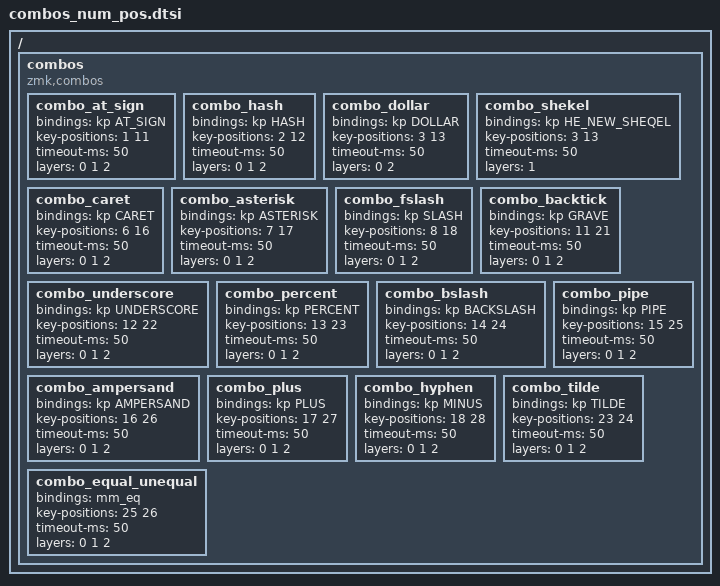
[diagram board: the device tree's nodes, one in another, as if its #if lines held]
/*
* KEY POSITIONS
* 34 Key Matrix
* ╭─────────────────────╮ ╭─────────────────────╮
* │ LT4 LT3 LT2 LT1 LT0 │ │ RT0 RT1 RT2 RT3 RT4 │
* │ LM4 LM3 LM2 LM1 LM0 │ │ RM0 RM1 RM2 RM3 RM4 │
* │ LB4 LB3 LB2 LB1 LB0 │ │ RB0 RB1 RB2 RB3 RB4 │
* ╰───────────╮ LH1 LH0 │ │ RH0 RH1 ╭───────────╯
*             ╰─────────╯ ╰─────────╯ 
*
* ╭────────────────╮ ╭────────────────╮
* │  0  1  2  3  4 │ │  5  6  7  8  9 │
* │ 10 11 12 13 14 │ │ 15 16 17 18 19 │
* │ 20 21 22 23 24 │ │ 25 26 27 28 29 │
* ╰─────────╮ 30 31│ │ 32 33╭─────────╯
*           ╰──────╯ ╰──────╯   
*
* 32 Key Matrix
* ╭────────────────╮ ╭────────────────╮
* │  0  1  2  3  4 │ │  5  6  7  8  9 │
* │ 10 11 12 13 14 │ │ 15 16 17 18 19 │
* ╰──╮ 20 21 22 23 │ │ 24 25 26 27 ╭──╯
*    ╰─────╮ 28 29 │ │ 30 31 ╭─────╯
*          ╰───────╯ ╰───────╯     
* 30 Key Matrix      
* ╭────────────────╮ ╭────────────────╮
* │  0  1  2  3  4 │ │  5  6  7  8  9 │
* │ 10 11 12 13 14 │ │ 15 16 17 18 19 │
* ╰──╮ 20 21 22    │ │    23 24 25 ╭──╯
*    ╰─────╮ 26 27 │ │ 28 29 ╭─────╯
*          ╰───────╯ ╰───────╯    
*/

/*
* Source: https://github.com/caksoylar/zmk-config
*/

#define COMBO(NAME, BINDINGS, KEYPOS, LAYERS, TERM, QUICKTAP, ...) \
    combo_##NAME { \
        timeout-ms = <TERM>; \
        bindings = <BINDINGS>; \
        key-positions = <KEYPOS>; \
        layers = <LAYERS>; \
        require-prior-idle-ms = <QUICKTAP>; \
		__VA_ARGS__ \
    };

/ {
    combos {
        compatible = "zmk,combos";

// Layers
#ifdef 34_KEY
COMBO(english,        &to ENG,        30 33, ENG SYS FUN BLTH,     50, 50)
COMBO(heb_to_eng,     &to ENG,        30 33, HEB,                  50, 50)
#endif
#ifdef 32_KEY
COMBO(english,        &to ENG,        28 31, ENG SYS FUN BLTH,     50, 50)
COMBO(heb_to_eng,     &to ENG,        28 31, HEB,                  50, 50)
#endif
#ifdef 30_KEY
COMBO(english,        &to ENG,        26 29, ENG SYS FUN BLTH,     50, 50)
COMBO(heb_to_eng,     &to ENG,        26 29, HEB,                  50, 50)
#endif

COMBO(hebrew,         &to_heb,        14 15, ENG SYS FUN BLTH,     50, 50)
COMBO(blth_l,         &to BLTH,       1 2 3, ENG HEB SYS FUN BLTH, 50, 50)
COMBO(blth_r,         &to BLTH,       6 7 8, ENG HEB SYS FUN BLTH, 50, 50)
        
// General
COMBO(capsword,       &caps_word,     4 5,   ENG HEB,              50, 50)
COMBO(alt_tab,        &mm_altb,       0 10,  ENG HEB SYS FUN,      50, 50)
COMBO(escape,         &kp ESCAPE,     4 14,  ENG HEB SYS FUN,      50, 50)
COMBO(bspc_del,       &mm_back_del,   5 15,  ENG HEB SYS FUN,      50, 50)
COMBO(return,         &kp RETURN,     9 19,  ENG HEB SYS FUN,      50, 50)

// Shortcuts
COMBO(copy,           &kp LC(C),      0 1,   ENG HEB SYS FUN,      50, 50)
COMBO(paste,          &mm_paste,      8 9,   ENG HEB SYS FUN,      50, 50)
COMBO(undo,           &kp LC(Z),      0 11,  ENG HEB SYS FUN,      50, 50)
COMBO(redo,           &kp LC(Y),      9 18,  ENG HEB SYS FUN,      50, 50)

// Top Row

// Left
COMBO(lte,            &mm_le,         1 2,   ENG SYS,              50, 50)
COMBO(h_lte,          &mm_hle,        1 2,   ENG SYS,              50, 50)
COMBO(brkt_brce_l,    &kp LBKT,       2 3,   ENG SYS,              50, 50)
COMBO(h_brkt_brce_l,  &kp HE_LBKT,    2 3,   ENG SYS,              50, 50)
COMBO(par_l,          &kp LPAR,       3 4,   ENG SYS,              50, 50)
COMBO(h_par_l,        &kp HE_LPAR,    3 4,   ENG SYS,              50, 50)
// Right
COMBO(par_r,          &kp RPAR,       3 4,   ENG SYS,              50, 50)
COMBO(h_par_r,        &kp HE_RPAR,    3 4,   ENG SYS,              50, 50)
COMBO(brkt_brce_r,    &kp RBKT,       2 3,   ENG SYS,              50, 50)
COMBO(h_brkt_brce_r,  &kp HE_RBKT,    2 3,   ENG SYS,              50, 50)
COMBO(gte,            &mm_ge,         1 2,   ENG SYS,              50, 50)
COMBO(h_gte,          &mm_hge,        1 2,   ENG SYS,              50, 50)

        // Top-Home 
        // Left

        combo_at_sign {
            bindings = <&kp AT_SIGN>;
            key-positions = <1 11>;
            timeout-ms = <50>;
            layers = <0 1 2>;
        };

        combo_hash {
            bindings = <&kp HASH>;
            key-positions = <2 12>;
            timeout-ms = <50>;
            layers = <0 1 2>;
        };

        combo_dollar {
            bindings = <&kp DOLLAR>;
            key-positions = <3 13>;
            timeout-ms = <50>;
            layers = <0 2>;
        };

        combo_shekel {
            bindings = <&kp HE_NEW_SHEQEL>;
            key-positions = <3 13>;
            timeout-ms = <50>;
            layers = <1>;
        };

        // Right

        combo_caret {
            bindings = <&kp CARET>;
            key-positions = <6 16>;
            timeout-ms = <50>;
            layers = <0 1 2>;
        };

        combo_asterisk {
            bindings = <&kp ASTERISK>;
            key-positions = <7 17>;
            timeout-ms = <50>;
            layers = <0 1 2>;
        };

        combo_fslash {
            bindings = <&kp SLASH>;
            key-positions = <8 18>;
            timeout-ms = <50>;
            layers = <0 1 2>;
        };

        // Home-Bottom

        combo_backtick {
            bindings = <&kp GRAVE>;
            key-positions = <11 21>;
            timeout-ms = <50>;
            layers = <0 1 2>;
        };

        combo_underscore {
            bindings = <&kp UNDERSCORE>;
            key-positions = <12 22>;
            timeout-ms = <50>;
            layers = <0 1 2>;
        };

        combo_percent {
            bindings = <&kp PERCENT>;
            key-positions = <13 23>;
            timeout-ms = <50>;
            layers = <0 1 2>;
        };

        combo_bslash {
            bindings = <&kp BACKSLASH>;
            key-positions = <14 24>;
            timeout-ms = <50>;
            layers = <0 1 2>;
        };

        // Left

        combo_pipe {
            bindings = <&kp PIPE>;
            key-positions = <15 25>;
            timeout-ms = <50>;
            layers = <0 1 2>;
        };

        combo_ampersand {
            bindings = <&kp AMPERSAND>;
            key-positions = <16 26>;
            timeout-ms = <50>;
            layers = <0 1 2>;
        };

        combo_plus {
            bindings = <&kp PLUS>;
            key-positions = <17 27>;
            timeout-ms = <50>;
            layers = <0 1 2>;
        };

        combo_hyphen {
            bindings = <&kp MINUS>;
            key-positions = <18 28>;
            timeout-ms = <50>;
            layers = <0 1 2>;
        };

        // Bottom Row (left to right)
        // Left

        combo_tilde {
            bindings = <&kp TILDE>;
            key-positions = <23 24>;
            timeout-ms = <50>;
            layers = <0 1 2>;
        };

        // Right

        combo_equal_unequal {
            bindings = <&mm_eq>;
            key-positions = <25 26>;
            timeout-ms = <50>;
            layers = <0 1 2>;
        };
    };
}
